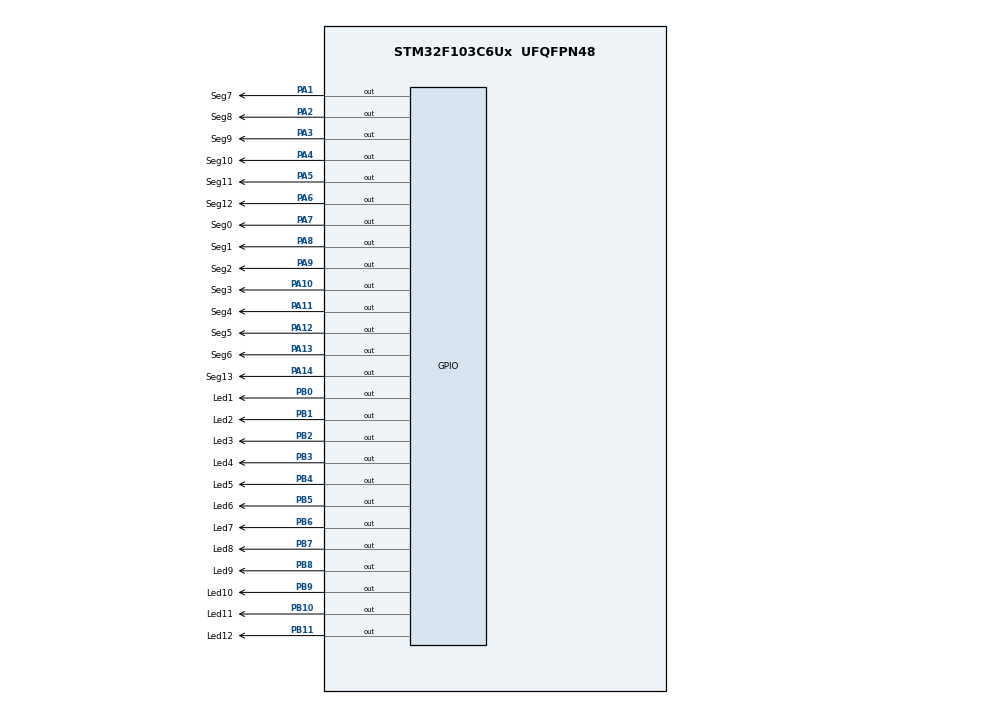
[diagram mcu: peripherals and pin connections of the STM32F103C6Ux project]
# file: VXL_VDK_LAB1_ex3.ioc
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Mcu.Family=STM32F1
Mcu.Name=STM32F103C6Ux
Mcu.Package=UFQFPN48
NVIC.PriorityGroup=NVIC_PRIORITYGROUP_4
PA1.GPIO_Label=Seg7
PA1.Signal=GPIO_Output
PA10.GPIO_Label=Seg3
PA10.Signal=GPIO_Output
PA11.GPIO_Label=Seg4
PA11.Signal=GPIO_Output
PA12.GPIO_Label=Seg5
PA12.Signal=GPIO_Output
PA13.GPIO_Label=Seg6
PA13.Signal=GPIO_Output
PA14.GPIO_Label=Seg13
PA14.Signal=GPIO_Output
PA2.GPIO_Label=Seg8
PA2.Signal=GPIO_Output
PA3.GPIO_Label=Seg9
PA3.Signal=GPIO_Output
PA4.GPIO_Label=Seg10
PA4.Signal=GPIO_Output
PA5.GPIO_Label=Seg11
PA5.Signal=GPIO_Output
PA6.GPIO_Label=Seg12
PA6.Signal=GPIO_Output
PA7.GPIO_Label=Seg0
PA7.Signal=GPIO_Output
PA8.GPIO_Label=Seg1
PA8.Signal=GPIO_Output
PA9.GPIO_Label=Seg2
PA9.Signal=GPIO_Output
PB0.GPIO_Label=Led1
PB0.Signal=GPIO_Output
PB1.GPIO_Label=Led2
PB1.Signal=GPIO_Output
PB10.GPIO_Label=Led11
PB10.Signal=GPIO_Output
PB11.GPIO_Label=Led12
PB11.Signal=GPIO_Output
PB2.GPIO_Label=Led3
PB2.Signal=GPIO_Output
PB3.GPIO_Label=Led4
PB3.Signal=GPIO_Output
PB4.GPIO_Label=Led5
PB4.Signal=GPIO_Output
PB5.GPIO_Label=Led6
PB5.Signal=GPIO_Output
PB6.GPIO_Label=Led7
PB6.Signal=GPIO_Output
PB7.GPIO_Label=Led8
PB7.Signal=GPIO_Output
PB8.GPIO_Label=Led9
PB8.Signal=GPIO_Output
PB9.GPIO_Label=Led10
PB9.Signal=GPIO_Output
ProjectManager.HeapSize=0x200
ProjectManager.StackSize=0x400
ProjectManager.TargetToolchain=STM32CubeIDE
RCC.APB1Freq_Value=8000000
RCC.APB2Freq_Value=8000000
VP_SYS_VS_ND.Mode=No_Debug
board=custom

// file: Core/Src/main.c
/* USER CODE BEGIN Header */
/**
  ******************************************************************************
  * @file           : main.c
  * @brief          : Main program body
  ******************************************************************************
  * @attention
  *
  * <h2><center>&copy; Copyright (c) 2024 STMicroelectronics.
  * All rights reserved.</center></h2>
  *
  * This software component is licensed by ST under BSD 3-Clause license,
  * the "License"; You may not use this file except in compliance with the
  * License. You may obtain a copy of the License at:
  *                        opensource.org/licenses/BSD-3-Clause
  *
  ******************************************************************************
  */
/* USER CODE END Header */
#include "main.h"

void SystemClock_Config(void);
static void MX_GPIO_Init(void);

/* USER CODE BEGIN 0 */
void clearAllClock(){
	HAL_GPIO_WritePin(Led1_GPIO_Port, Led1_Pin, 0);
	HAL_GPIO_WritePin(Led2_GPIO_Port, Led2_Pin, 0);
	HAL_GPIO_WritePin(Led3_GPIO_Port, Led3_Pin, 0);
	HAL_GPIO_WritePin(Led4_GPIO_Port, Led4_Pin, 0);
	HAL_GPIO_WritePin(Led5_GPIO_Port, Led5_Pin, 0);
	HAL_GPIO_WritePin(Led6_GPIO_Port, Led6_Pin, 0);
	HAL_GPIO_WritePin(Led7_GPIO_Port, Led7_Pin, 0);
	HAL_GPIO_WritePin(Led8_GPIO_Port, Led8_Pin, 0);
	HAL_GPIO_WritePin(Led9_GPIO_Port, Led9_Pin, 0);
	HAL_GPIO_WritePin(Led10_GPIO_Port, Led10_Pin, 0);
	HAL_GPIO_WritePin(Led11_GPIO_Port, Led11_Pin, 0);
	HAL_GPIO_WritePin(Led12_GPIO_Port, Led12_Pin, 0);
}
void clearNumberOnClock(int num){
	int count = num % 12;
	switch(count){
		case 1:
			HAL_GPIO_WritePin(Led1_GPIO_Port, Led1_Pin, 0);
			break;
		case 2:
			HAL_GPIO_WritePin(Led2_GPIO_Port, Led2_Pin, 0);
			break;
		case 3:
			HAL_GPIO_WritePin(Led3_GPIO_Port, Led3_Pin, 0);
			break;
		case 4:
			HAL_GPIO_WritePin(Led4_GPIO_Port, Led4_Pin, 0);
			break;
		case 5:
			HAL_GPIO_WritePin(Led5_GPIO_Port, Led5_Pin, 0);
			break;
		case 6:
			HAL_GPIO_WritePin(Led6_GPIO_Port, Led6_Pin, 0);
			break;
		case 7:
			HAL_GPIO_WritePin(Led7_GPIO_Port, Led7_Pin, 0);
			break;
		case 8:
			HAL_GPIO_WritePin(Led8_GPIO_Port, Led8_Pin, 0);
			break;
		case 9:
			HAL_GPIO_WritePin(Led9_GPIO_Port, Led9_Pin, 0);
			break;
		case 10:
			HAL_GPIO_WritePin(Led10_GPIO_Port, Led10_Pin, 0);
			break;
		case 11:
			HAL_GPIO_WritePin(Led11_GPIO_Port, Led11_Pin, 0);
			break;
		case 12:
			HAL_GPIO_WritePin(Led12_GPIO_Port, Led12_Pin, 0);
			break;
		default:
			HAL_GPIO_WritePin(Led12_GPIO_Port, Led12_Pin, 0);
			break;
		}
}
void setNumberOnClock(int num){
	//clearAllClock();
	int count = num % 12;
	switch(count){
	case 1:
		HAL_GPIO_WritePin(Led1_GPIO_Port, Led1_Pin, 1);
		break;
	case 2:
		HAL_GPIO_WritePin(Led2_GPIO_Port, Led2_Pin, 1);
		break;
	case 3:
		HAL_GPIO_WritePin(Led3_GPIO_Port, Led3_Pin, 1);
		break;
	case 4:
		HAL_GPIO_WritePin(Led4_GPIO_Port, Led4_Pin, 1);
		break;
	case 5:
		HAL_GPIO_WritePin(Led5_GPIO_Port, Led5_Pin, 1);
		break;
	case 6:
		HAL_GPIO_WritePin(Led6_GPIO_Port, Led6_Pin, 1);
		break;
	case 7:
		HAL_GPIO_WritePin(Led7_GPIO_Port, Led7_Pin, 1);
		break;
	case 8:
		HAL_GPIO_WritePin(Led8_GPIO_Port, Led8_Pin, 1);
		break;
	case 9:
		HAL_GPIO_WritePin(Led9_GPIO_Port, Led9_Pin, 1);
		break;
	case 10:
		HAL_GPIO_WritePin(Led10_GPIO_Port, Led10_Pin, 1);
		break;
	case 11:
		HAL_GPIO_WritePin(Led11_GPIO_Port, Led11_Pin, 1);
		break;
	case 12:
		HAL_GPIO_WritePin(Led12_GPIO_Port, Led12_Pin, 1);
		break;
	default:
		HAL_GPIO_WritePin(Led12_GPIO_Port, Led12_Pin, 1);
		break;
	}
}
/* USER CODE END 0 */

int main(void)
{

  /* MCU Configuration--------------------------------------------------------*/

  /* Reset of all peripherals, Initializes the Flash interface and the Systick. */
  HAL_Init();

  /* Configure the system clock */
  SystemClock_Config();

  /* Initialize all configured peripherals */
  MX_GPIO_Init();

  /* Infinite loop */
  /* USER CODE BEGIN WHILE */
  //int count = 1;
  int hour = 0;
  int min = 0;
  int sec = 0;
  clearAllClock();
  while (1)
  {
	  clearNumberOnClock(sec);
	  clearNumberOnClock(min);
	  clearNumberOnClock(hour);
	  sec++;
	  if(sec >= 60){
		  sec = 0;
		  min++;
	  }
	  if(min >= 60){
		  min = 0;
		  hour++;
	  }
	  if(hour >= 12){
		  hour = 0;
		  //clearAllClock();
	  }
	  setNumberOnClock(sec);
	  setNumberOnClock(min);
	  setNumberOnClock(hour);

	  HAL_Delay(1000);
    /* USER CODE END WHILE */

  }
}

void SystemClock_Config(void)
{
  RCC_OscInitTypeDef RCC_OscInitStruct = {0};
  RCC_ClkInitTypeDef RCC_ClkInitStruct = {0};

  /** Initializes the RCC Oscillators according to the specified parameters
  * in the RCC_OscInitTypeDef structure.
  */
  RCC_OscInitStruct.OscillatorType = RCC_OSCILLATORTYPE_HSI;
  RCC_OscInitStruct.HSIState = RCC_HSI_ON;
  RCC_OscInitStruct.HSICalibrationValue = RCC_HSICALIBRATION_DEFAULT;
  RCC_OscInitStruct.PLL.PLLState = RCC_PLL_NONE;
  if (HAL_RCC_OscConfig(&RCC_OscInitStruct) != HAL_OK)
  {
    Error_Handler();
  }
  /** Initializes the CPU, AHB and APB buses clocks
  */
  RCC_ClkInitStruct.ClockType = RCC_CLOCKTYPE_HCLK|RCC_CLOCKTYPE_SYSCLK
                              |RCC_CLOCKTYPE_PCLK1|RCC_CLOCKTYPE_PCLK2;
  RCC_ClkInitStruct.SYSCLKSource = RCC_SYSCLKSOURCE_HSI;
  RCC_ClkInitStruct.AHBCLKDivider = RCC_SYSCLK_DIV1;
  RCC_ClkInitStruct.APB1CLKDivider = RCC_HCLK_DIV1;
  RCC_ClkInitStruct.APB2CLKDivider = RCC_HCLK_DIV1;

  if (HAL_RCC_ClockConfig(&RCC_ClkInitStruct, FLASH_LATENCY_0) != HAL_OK)
  {
    Error_Handler();
  }
}

static void MX_GPIO_Init(void)
{
  GPIO_InitTypeDef GPIO_InitStruct = {0};

  /* GPIO Ports Clock Enable */
  __HAL_RCC_GPIOA_CLK_ENABLE();

  /*Configure GPIO pin Output Level */
  HAL_GPIO_WritePin(GPIOA, Led1_Pin|Led2_Pin|Led3_Pin|Led4_Pin
                          |Led5_Pin|Led6_Pin|Led7_Pin|Led8_Pin
                          |Led9_Pin|Led10_Pin|Led11_Pin|Led12_Pin, GPIO_PIN_RESET);

  /*Configure GPIO pins : Led1_Pin Led2_Pin Led3_Pin Led4_Pin
                           Led5_Pin Led6_Pin Led7_Pin Led8_Pin
                           Led9_Pin Led10_Pin Led11_Pin Led12_Pin */
  GPIO_InitStruct.Pin = Led1_Pin|Led2_Pin|Led3_Pin|Led4_Pin
                          |Led5_Pin|Led6_Pin|Led7_Pin|Led8_Pin
                          |Led9_Pin|Led10_Pin|Led11_Pin|Led12_Pin;
  GPIO_InitStruct.Mode = GPIO_MODE_OUTPUT_PP;
  GPIO_InitStruct.Pull = GPIO_NOPULL;
  GPIO_InitStruct.Speed = GPIO_SPEED_FREQ_LOW;
  HAL_GPIO_Init(GPIOA, &GPIO_InitStruct);

}

void Error_Handler(void)
{
  __disable_irq();
  while (1)
  {
  }
}

/************************ (C) COPYRIGHT STMicroelectronics *****END OF FILE****/
